# STM32WB50xx register map
File version: 1.0
Registers are 32-bit, read-write, reset 0x0 unless marked. A register's access mark holds for its fields unless they carry their own. Offsets are from the block's base; [hi:lo] are bit positions; {n}, {i} and the like mark numbered series.

## PWR — Power Control
Base 0x58000400
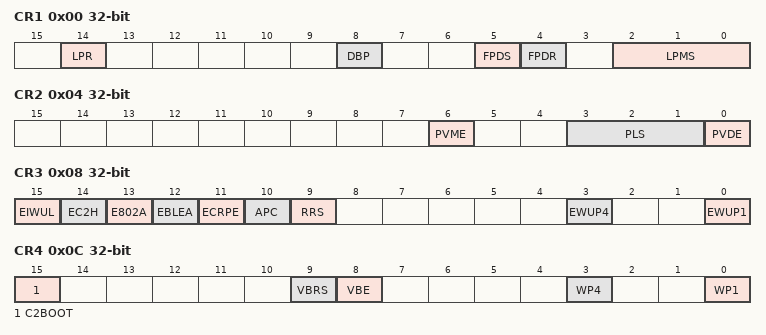
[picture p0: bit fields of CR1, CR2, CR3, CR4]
0x00 CR1 — PWR Power Control Register 1
  [14] LPR — Regulator Low-Power Run mode
  [8] DBP — Disable Backup Domain write protection
  [5] FPDS — Flash power down mode during LPsleep for CPU1
    0=IDLE; 1=POWER_DOWN
  [4] FPDR — Flash power down mode during LPrun for CPU1
    0=IDLE; 1=POWER_DOWN
  [2:0] LPMS — Low Power Mode Selection for CPU1
    0=STOP0; 1=STOP1; 2=STOP2; 3=STANDBY; 4=SHUTDOWN
0x04 CR2 — PWR Power Control Register 2
  [6] PVME — Peripherical Voltage Monitor Enable for all power domains
  [3:1] PLS — Power voltage detector level selection
    {v}=PVDLEVEL_{v} (v=0..7)
  [0] PVDE — Power voltage detector enable
0x08 CR3 — PWR Power Control Register 3
  [15] EIWUL — Internal Wake-Up line interrupt for CPU1
  [14] EC2H — CPU2 Hold interrupt for CPU1
  [13] E802A — 802.15.4 end of activity interrupt for CPU1
  [12] EBLEA — BLE end of activity interrupt for CPU1
  [11] ECRPE — Critical radio phase end of activity interrupt for CPU1
  [10] APC — Apply pull-up and pull-down configuration for CPU1
  [9] RRS — SRAM2 retention in STANDBY mode
  [3] EWUP4 — Enable external WKUP Pin 4 [line 3]
  [0] EWUP1 — Enable external WKUP Pin 1 [line 0]
0x0C CR4 — PWR Power Control Register 4
  [15] C2BOOT — Boot CPU2 after reset or wakeup from Stop or Standby modes
  [9] VBRS — VBAT battery charging resistor selection
    0=CHARG_RESISTOR_5K; 1=CHARGRESISTOR_1_5K
  [8] VBE — VBAT battery charging enable
  [3] WP4 — Wake-Up Pin 4 [line 3] polarity
  [0] WP1 — Wake-Up Pin 1 [line 0] polarity
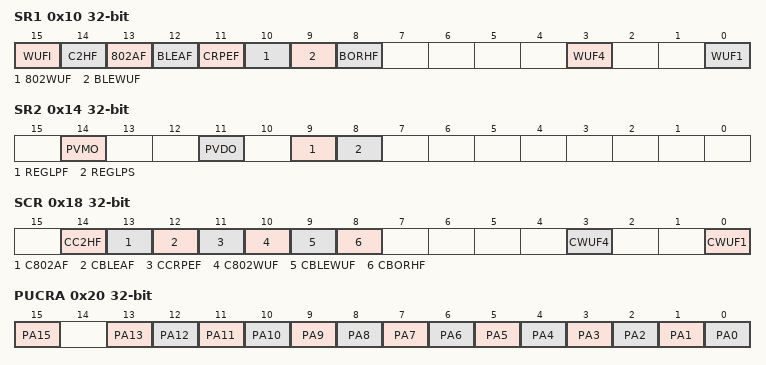
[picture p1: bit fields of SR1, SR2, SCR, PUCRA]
0x10 SR1 — PWR Power Status Register 1
  [15] WUFI — Internal wakeup interrupt flag
  [14] C2HF — CPU2 Hold interrupt flag
  [13] 802AF — 802.15.4 end of activity interrupt flag
  [12] BLEAF — BLE end of activity interrupt flag
  [11] CRPEF — Critical radio phase end of activity interrupt flag
  [10] 802WUF — 802.15.4 wakeup interrupt flag
  [9] BLEWUF — BLE wakeup interrupt flag
  [8] BORHF — BORH interrupt flag
  [3] WUF4 — Wakeup Pin 4 [Flag 3]
  [0] WUF1 — Wakeup Pin 1 [Flag 0]
0x14 SR2 — PWR Power Status Register 2
  [14] PVMO — Peripheral voltage monitor output for all power domains
  [11] PVDO — Power voltage detector output
  [9] REGLPF — Low-power regulator flag
  [8] REGLPS — Low-power regulator started
0x18 SCR — PWR Power Status Reset Register
  [14] CC2HF — Clear CPU2 Hold interrupt flag
  [13] C802AF — Clear 802.15.4 end of activity interrupt flag
  [12] CBLEAF — Clear BLE end of activity interrupt flag
  [11] CCRPEF — Clear Critical radio phase end of activity interrupt flag
  [10] C802WUF — Clear 802.15.4 wakeup interrupt flag
  [9] CBLEWUF — Clear BLE wakeup interrupt flag
  [8] CBORHF — Clear BORH interrupt flag
  [3] CWUF4 — Clear Wake-up Pin 4 [Flag 3]
  [0] CWUF1 — Clear Wake-up Pin 1 [Flag 0]
0x1C CR5 — PWR Power Control Register 5
0x20 PUCRA — PWR Pull-Up Control Register of port A
  [15] PA15 — Pin PA15 Pull-Up set
  [n] PA{n} (n=0..13) — Pin PA{n} Pull-Up set
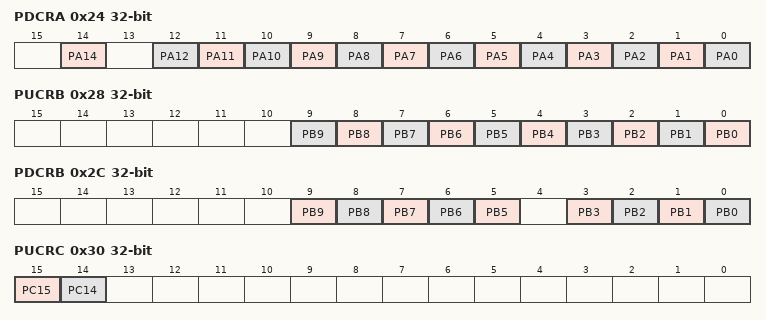
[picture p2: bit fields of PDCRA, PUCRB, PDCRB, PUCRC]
0x24 PDCRA — PWR Pull-Down Control Register of port A
  [14] PA14 — Pin PA14 Pull-Down set
  [n] PA{n} (n=0..12) — Pin PA{n} Pull-Down set
0x28 PUCRB — PWR Pull-Up Control Register of port B
  [n] PB{n} (n=0..9) — Pin PB{n} Pull-Up set
0x2C PDCRB — PWR Pull-Down Control Register of port B
  [n] PB{n} (n=5..9) — Pin PB{n} Pull-Down set
  [n] PB{n} (n=0..3) — Pin PB{n} Pull-Down set
0x30 PUCRC — PWR Pull-Up Control Register of port C
  [15] PC15 — Pin PC15 Pull-Up set
  [14] PC14 — Pin PC14 Pull-Up set
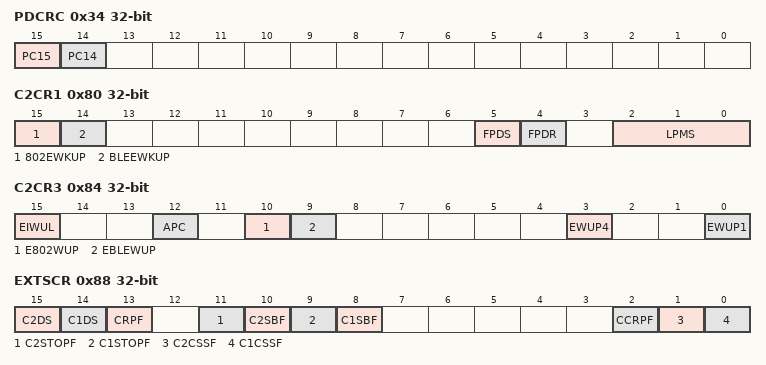
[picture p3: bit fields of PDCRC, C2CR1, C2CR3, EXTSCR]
0x34 PDCRC — PWR Pull-Down Control Register of port C
  [15] PC15 — Pin PC15 Pull-Down set
  [14] PC14 — Pin PC14 Pull-Down set
0x40 PUCRE — PWR Pull-Up Control Register of port E
  [4] PE4 — Pin PE4 Pull-Up set
0x44 PDCRE — PWR Pull-Down Control Register of port E
  [4] PE4 — Pin PE4 Pull-Down set
0x58 PUCRH — PWR Pull-Up Control Register of port H
  [3] PH3 — Pin PH3 Pull-Up set
0x5C PDCRH — PWR Pull-Down Control Register of port H
  [3] PH3 — Pin PH3 Pull-Down set
0x80 C2CR1 — PWR Power Control Register 1 for CPU2
  [15] 802EWKUP — Radio 802.15.4 external wakeup signal
  [14] BLEEWKUP — Radio BLE external wakeup signal
  [5] FPDS — Flash power down mode during LPsleep for CPU2
    0=IDLE; 1=POWER_DOWN
  [4] FPDR — Flash power down mode during LPrun for CPU2
    0=IDLE; 1=POWER_DOWN
  [2:0] LPMS — Low Power Mode Selection for CPU2
    0=STOP0; 1=STOP1; 2=STOP2; 3=STANDBY; 4=SHUTDOWN
0x84 C2CR3 — PWR Power Control Register 3 for CPU2
  [15] EIWUL — Internal Wake-Up line interrupt for CPU2
  [12] APC — Apply pull-up and pull-down configuration for CPU2
  [10] E802WUP — Enable BLE host wakeup interrupt for CPU2
  [9] EBLEWUP — Enable BLE host wakeup interrupt for CPU2
  [3] EWUP4 — Enable external WKUP Pin 4 [line 3] for CPU2
  [0] EWUP1 — Enable external WKUP Pin 1 [line 0] for CPU2
0x88 EXTSCR — PWR Power Status Reset Register for CPU2
  [15] C2DS — CPU2 deepsleep mode flag
  [14] C1DS — CPU1 deepsleep mode flag
  [13] CRPF — Critical radio system phase flag
  [11] C2STOPF — System stop flag for CPU2
  [10] C2SBF — System standby flag for CPU2
  [9] C1STOPF — System stop flag for CPU1
  [8] C1SBF — System standby flag for CPU1
  [2] CCRPF — Clear critical radio system phase flag
  [1] C2CSSF — Clear standby and stop flags for CPU2
  [0] C1CSSF — Clear standby and stop flags for CPU1
